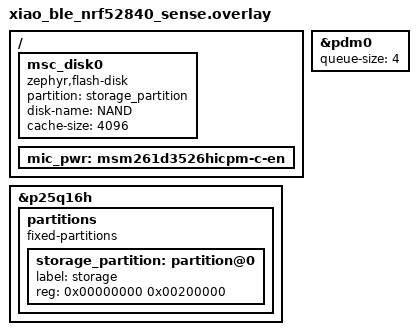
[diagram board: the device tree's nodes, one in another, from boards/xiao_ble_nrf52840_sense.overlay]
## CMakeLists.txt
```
#-------------------------------------------------------------------------------
# Zephyr Example Application
#
# Copyright (c) 2021 Nordic Semiconductor ASA
# SPDX-License-Identifier: Apache-2.0

cmake_minimum_required(VERSION 3.13.1)

# ZEPHYR_EXTRA_MODULES must be set BEFORE find_package(Zephyr) so that
# the module is discovered and its CMakeLists.txt (zephyr_include_directories,
# zephyr_library_sources, …) is processed during the Zephyr configuration.
list(APPEND ZEPHYR_EXTRA_MODULES ${CMAKE_CURRENT_SOURCE_DIR}/model)

find_package(Zephyr REQUIRED HINTS $ENV{ZEPHYR_BASE})

project(app LANGUAGES C CXX)

target_sources(app PRIVATE src/main.c)

if(CONFIG_APP_PITCH OR CONFIG_APP_REC OR CONFIG_APP_KWS)
    target_sources(app PRIVATE src/mic.c)
endif()
if(CONFIG_APP_PITCH)
    target_sources(app PRIVATE src/pitch.c)
endif()
if(CONFIG_APP_REC)
    target_sources(app PRIVATE src/rec.c)
endif()
if(CONFIG_APP_KWS)
    target_sources(app PRIVATE src/kws.cpp)
endif()
if(CONFIG_APP_DISPLAY_UI)
    target_sources(app PRIVATE src/display_ui.c)
endif()
if(CONFIG_APP_IMU)
    target_sources(app PRIVATE src/imu.c)
endif()
```

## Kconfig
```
# Copyright (c) 2021 Nordic Semiconductor ASA
# SPDX-License-Identifier: Apache-2.0
#
# This file is the application Kconfig entry point. All application Kconfig
# options can be defined here or included via other application Kconfig files.
# You can browse these options using the west targets menuconfig (terminal) or
# guiconfig (GUI).

menu "Zephyr"
source "Kconfig.zephyr"
endmenu

module = APP
module-str = APP
source "subsys/logging/Kconfig.template.log_config"

config APP_PITCH
	bool "Pitch detection"
	help
	  Real-time monophonic pitch detector (MPM algorithm).
	  Shell commands: pitch start/stop/status.

config APP_REC
	bool "WAV recording"
	help
	  WAV recording to the external QSPI flash via FAT.
	  Requires FILE_SYSTEM and FAT_FILESYSTEM_ELM.
	  Shell commands: record start/stop/status.

config APP_KWS
	bool "Keyword spotting"
	help
	  Keyword spotting using the Edge Impulse SDK.
	  Requires EDGE_IMPULSE_SDK, CPP, and GLIBCXX_LIBCPP.
	  Shell commands: kws start/stop/status.

config APP_IMU
	bool "IMU motion detection"
	default y
	depends on I2C && GPIO
	help
	  Enable significant motion detection using the LSM6DS3TR-C IMU on
	  the XIAO BLE Sense.  Events are logged at INF level via the "imu"
	  log module.  The module starts automatically at boot via SYS_INIT.
	  Requires LSM6DSL_TRIGGER_NONE so that this module owns the INT1
	  GPIO line (set CONFIG_LSM6DSL_TRIGGER_NONE=y in prj.conf).

config APP_DISPLAY_UI
	bool "Round display UI (LVGL)"
	depends on LVGL && DISPLAY && APP_PITCH
	select LV_FONT_MONTSERRAT_32
	help
	  Enable the LVGL-based round display UI for the Seeed XIAO Round Display.
	  Build with --shield seeed_xiao_round_display.
```

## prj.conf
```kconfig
# Copyright (c) 2021 Nordic Semiconductor ASA
# SPDX-License-Identifier: Apache-2.0
#
# This file contains selected Kconfig options for the application.

# ---------------------------------------------------------------------------
# USB device (CDC-ACM shell); MSC disk is added by rec.conf
# ---------------------------------------------------------------------------
CONFIG_USB_DEVICE_STACK_NEXT=y
CONFIG_CDC_ACM_SERIAL_INITIALIZE_AT_BOOT=n
CONFIG_FLASH=y
# See Nordic known issue NCSDK-40096
CONFIG_UDC_BUF_POOL_SIZE=8192

# ---------------------------------------------------------------------------
# Round display UI – Seeed XIAO Round Display + LVGL
# ---------------------------------------------------------------------------
CONFIG_DISPLAY=y
CONFIG_LVGL=y
CONFIG_LV_Z_MEM_POOL_SYS_HEAP=y
# ~50 LVGL objects across the four screens; exhausting this pool trips
# LV_USE_ASSERT_MALLOC, which spins forever and starves the shell thread.
CONFIG_LV_Z_MEM_POOL_SIZE=49152
CONFIG_SPI=y
CONFIG_I2C=y
CONFIG_INPUT=y
CONFIG_LV_Z_POINTER_FROM_CHOSEN_TOUCH=y
CONFIG_APP_DISPLAY_UI=y

# Hardware info – used to generate a unique USB serial-number string
CONFIG_HWINFO=y

# ---------------------------------------------------------------------------
# Entropy / random number generator (required by the note game)
# ---------------------------------------------------------------------------
CONFIG_ENTROPY_GENERATOR=y

# ---------------------------------------------------------------------------
# IMU motion/tap detection – LSM6DS3TR-C
# ---------------------------------------------------------------------------
# SENSOR enables the subsystem (required for the lsm6dsl driver to compile).
# Use no-trigger mode so the imu module owns the INT1 GPIO line itself.
CONFIG_SENSOR=y
CONFIG_LSM6DSL_TRIGGER_NONE=y

# ---------------------------------------------------------------------------
# PDM microphone (used by pitch detection)
# ---------------------------------------------------------------------------
CONFIG_AUDIO=y
CONFIG_AUDIO_DMIC=y

# Regulator API (already selected by board defconfig; listed here for clarity)
CONFIG_REGULATOR=y

# Enable USB device stack internal warnings so enumeration issues are visible
CONFIG_USBD_LOG_LEVEL_WRN=y

# ---------------------------------------------------------------------------
# Shell (available immediately via USB CDC-ACM)
# ---------------------------------------------------------------------------
CONFIG_SHELL=y
CONFIG_SHELL_BACKEND_SERIAL=y
CONFIG_SHELL_STACK_SIZE=4096

CONFIG_LOG=y
CONFIG_MAIN_STACK_SIZE=4096

# Floating-point unit – required by pitch detection (MPM uses float math)
CONFIG_FPU=y

CONFIG_HEAP_MEM_POOL_SIZE=32768

# ---------------------------------------------------------------------------
# Application modules
# ---------------------------------------------------------------------------
CONFIG_APP_PITCH=y
```

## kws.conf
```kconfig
# Keyword spotting fragment
# Usage: west build ... -- -DEXTRA_CONF_FILE=kws.conf
CONFIG_APP_KWS=y

# C++ support required by the Edge Impulse SDK
CONFIG_CPP=y
CONFIG_GLIBCXX_LIBCPP=y

CONFIG_EDGE_IMPULSE_SDK=y
```

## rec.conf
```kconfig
# WAV recording fragment
# Usage: west build ... -- -DEXTRA_CONF_FILE=rec.conf
CONFIG_APP_REC=y

# Flash partition map and page-layout info (required by the disk driver)
CONFIG_FLASH_MAP=y
CONFIG_FLASH_PAGE_LAYOUT=y

# Expose the QSPI flash partition as a USB-MSC block device
CONFIG_DISK_DRIVER_FLASH=y
CONFIG_USBD_MSC_CLASS=y

# FAT filesystem on the QSPI flash
CONFIG_FILE_SYSTEM=y
CONFIG_FAT_FILESYSTEM_ELM=y
CONFIG_FS_FATFS_MOUNT_MKFS=y
CONFIG_FS_FATFS_EXTRA_NATIVE_API=y
```

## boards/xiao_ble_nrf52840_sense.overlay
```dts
/*
 * Copyright (c) 2024 Nordic Semiconductor ASA
 * SPDX-License-Identifier: Apache-2.0
 *
 * Expose the 2 MB on-board QSPI flash (P25Q16H) as a USB Mass Storage disk.
 * Enable the on-board PDM microphone for audio recording.
 *
 * The internal-flash storage_partition defined in
 * nrf52840_partition_uf2_sdv7.dtsi is deleted and re-created on the external
 * QSPI flash instead.  The msc_disk0 node ties the partition to the USB MSC
 * "NAND" LUN declared in main.c.
 */

/delete-node/ &storage_partition;

&p25q16h {
	partitions {
		compatible = "fixed-partitions";
		#address-cells = <1>;
		#size-cells = <1>;

		storage_partition: partition@0 {
			label = "storage";
			reg = <0x00000000 0x00200000>; /* 2 MB */
		};
	};
};

/ {
	msc_disk0 {
		compatible = "zephyr,flash-disk";
		partition = <&storage_partition>;
		disk-name = "NAND";
		cache-size = <4096>;
	};

	/* Add a label to the microphone power regulator so C code can obtain
	 * the device via DT_NODELABEL(mic_pwr) and call regulator_enable(). */
	mic_pwr: msm261d3526hicpm-c-en {};
};

/* PDM0 is disabled by default in the nRF52840 DTSI; enable it here.
 * The recording design uses a separate FAT-writer thread so the PDM reader
 * frees slab blocks almost immediately (just a memcpy).  queue-size=4 is
 * therefore sufficient: 2 (HW double-buffer) + 2 (rx_queue margin) = 4. */
&pdm0 {
	status = "okay";
	queue-size = <4>;
};
```

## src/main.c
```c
/*
 * Copyright (c) 2021 Nordic Semiconductor ASA
 * SPDX-License-Identifier: Apache-2.0
 */

#include <zephyr/kernel.h>
#include <zephyr/logging/log.h>
#include <zephyr/usb/usbd.h>
#if IS_ENABLED(CONFIG_APP_REC)
#include <zephyr/usb/class/usbd_msc.h>
#include <zephyr/storage/disk_access.h>
#endif

#include <app_version.h>

LOG_MODULE_REGISTER(main, CONFIG_APP_LOG_LEVEL);

/* ===========================================================================
 * USB device setup (CDC-ACM shell; composite with MSC when APP_REC is enabled)
 * =========================================================================== */

/* VID 0x2FE3 is the Zephyr project vendor ID -- replace with your own. */
USBD_DEVICE_DEFINE(usbd_dev,
   DEVICE_DT_GET(DT_NODELABEL(zephyr_udc0)),
   0x2FE3, 0x0008);

USBD_DESC_LANG_DEFINE(usbd_lang);
USBD_DESC_MANUFACTURER_DEFINE(usbd_mfr, "Seeed Studio");
#if IS_ENABLED(CONFIG_APP_REC)
USBD_DESC_PRODUCT_DEFINE(usbd_product, "XIAO BLE Flash Disk");
#else
USBD_DESC_PRODUCT_DEFINE(usbd_product, "XIAO BLE Microphone");
#endif

#if defined(CONFIG_HWINFO)
USBD_DESC_SERIAL_NUMBER_DEFINE(usbd_sn);
#endif

USBD_DESC_CONFIG_DEFINE(usbd_fs_cfg_desc, "FS Configuration");
USBD_CONFIGURATION_DEFINE(usbd_fs_config, 0, 125, &usbd_fs_cfg_desc);

#if IS_ENABLED(CONFIG_APP_REC)
/* "NAND" must match disk-name in the board overlay */
USBD_DEFINE_MSC_LUN(nand, "NAND", "Seeed", "XIAO Flash", "0.01");
#endif

static const char *const usbd_blocklist[] = {NULL};

/* ===========================================================================
 * main -- init USB (and flash disk when APP_REC is enabled), then idle
 * =========================================================================== */

int main(void)
{
int ret;

#if IS_ENABLED(CONFIG_APP_REC)
ret = disk_access_init("NAND");
if (ret) {
LOG_ERR("disk_access_init: %d", ret);
return ret;
}
#endif

ret = usbd_add_descriptor(&usbd_dev, &usbd_lang);
if (ret) {
LOG_ERR("lang descriptor: %d", ret);
return ret;
}
ret = usbd_add_descriptor(&usbd_dev, &usbd_mfr);
if (ret) {
LOG_ERR("mfr descriptor: %d", ret);
return ret;
}
ret = usbd_add_descriptor(&usbd_dev, &usbd_product);
if (ret) {
LOG_ERR("product descriptor: %d", ret);
return ret;
}
#if defined(CONFIG_HWINFO)
ret = usbd_add_descriptor(&usbd_dev, &usbd_sn);
if (ret) {
LOG_ERR("sn descriptor: %d", ret);
return ret;
}
#endif
ret = usbd_add_configuration(&usbd_dev, USBD_SPEED_FS,
     &usbd_fs_config);
if (ret) {
LOG_ERR("add_configuration: %d", ret);
return ret;
}
ret = usbd_register_all_classes(&usbd_dev, USBD_SPEED_FS, 1,
usbd_blocklist);
if (ret) {
LOG_ERR("register_all_classes: %d", ret);
return ret;
}
#if defined(CONFIG_USBD_CDC_ACM_CLASS)
ret = usbd_device_set_code_triple(&usbd_dev, USBD_SPEED_FS,
  USB_BCC_MISCELLANEOUS, 0x02, 0x01);
if (ret) {
LOG_ERR("set_code_triple: %d", ret);
return ret;
}
#endif
ret = usbd_init(&usbd_dev);
if (ret) {
LOG_ERR("usbd_init: %d", ret);
return ret;
}
ret = usbd_enable(&usbd_dev);
if (ret) {
LOG_ERR("usbd_enable: %d", ret);
return ret;
}

LOG_INF("XIAO BLE Microphone ready (app %s) -- "
"connect USB and open the serial port", APP_VERSION_STRING);

while (true) {
k_sleep(K_SECONDS(1));
}

return 0;
}
```

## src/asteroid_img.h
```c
#pragma once
#include <lvgl.h>

static const uint8_t asteroid_img_map[] = {
    0x00, 0x00, 0x00, 0x00, 0x00, 0x00, 0x00, 0x00, 0x00, 0x00, 0xAA, 0x52,
    0xFF, 0xFF, 0x00, 0x00, 0x00, 0x00, 0xE8, 0x39, 0x8F, 0x6B, 0x31, 0x7C,
    0x6E, 0x6B, 0xA6, 0x31, 0x00, 0x00, 0x00, 0x00, 0x00, 0x00, 0xFF, 0x7F,
    0x00, 0x00, 0x00, 0x00, 0x00, 0x00, 0x00, 0x00, 0x00, 0x00, 0x00, 0x00,
    0x00, 0x00, 0xAA, 0x52, 0x00, 0x00, 0x00, 0x00, 0x00, 0x00, 0x82, 0x10,
    0x2D, 0x5B, 0x56, 0xA5, 0xF8, 0xB5, 0x35, 0x9D, 0xF4, 0x94, 0x15, 0x95,
    0x31, 0x7C, 0x8A, 0x4A, 0x00, 0x00, 0x00, 0x00, 0xFF, 0xFF, 0x00, 0x00,
    0x00, 0x00, 0x00, 0x00, 0x00, 0x00, 0x00, 0x00, 0x00, 0x00, 0x00, 0x00,
    0x00, 0x00, 0xE4, 0x18, 0x2D, 0x63, 0xD4, 0x8C, 0xD8, 0xAD, 0x97, 0xA5,
    0x97, 0xA5, 0x93, 0x8C, 0xCF, 0x73, 0xAF, 0x6B, 0x10, 0x74, 0x76, 0xA5,
    0xB3, 0x8C, 0xE8, 0x39, 0x00, 0x00, 0x55, 0xAD, 0x00, 0x00, 0x00, 0x00,
    0x00, 0x00, 0x00, 0x00, 0x00, 0x00, 0x29, 0x42, 0xAF, 0x6B, 0xF4, 0x94,
    0xD8, 0xAD, 0xD8, 0xAD, 0xB8, 0xAD, 0xD8, 0xAD, 0x97, 0xA5, 0xB7, 0xAD,
    0xD8, 0xAD, 0xB7, 0xAD, 0xB3, 0x8C, 0x2D, 0x5B, 0x35, 0x9D, 0x77, 0xA5,
    0xA6, 0x31, 0x00, 0x00, 0xEF, 0x7B, 0x00, 0x00, 0xFF, 0xFF, 0x00, 0x00,
    0x8F, 0x6B, 0xD4, 0x94, 0xB3, 0x8C, 0xD8, 0xAD, 0xB7, 0xAD, 0xF4, 0x94,
    0xF0, 0x73, 0xF0, 0x73, 0x56, 0xA5, 0x97, 0xA5, 0x97, 0xA5, 0x76, 0xA5,
    0xD8, 0xAD, 0x56, 0xA5, 0xD4, 0x8C, 0xF9, 0xB5, 0x93, 0x8C, 0xC3, 0x10,
    0x00, 0x00, 0xAA, 0x52, 0x00, 0x00, 0xCB, 0x52, 0x97, 0xA5, 0x2D, 0x63,
    0x15, 0x9D, 0xD8, 0xAD, 0xF0, 0x73, 0x0D, 0x5B, 0x11, 0x74, 0xAF, 0x63,
    0x8F, 0x6B, 0xF8, 0xB5, 0x15, 0x95, 0xEC, 0x52, 0xAF, 0x6B, 0xB7, 0xAD,
    0xB7, 0xAD, 0x76, 0xA5, 0xD8, 0xAD, 0xD0, 0x73, 0x00, 0x00, 0x00, 0x00,
    0x00, 0x00, 0x31, 0x7C, 0xAF, 0x6B, 0xF4, 0x94, 0x19, 0xB6, 0x93, 0x8C,
    0x2E, 0x5B, 0xF5, 0x8C, 0x36, 0x95, 0xF1, 0x6B, 0xAF, 0x6B, 0xF8, 0xB5,
    0x4E, 0x63, 0x72, 0x7C, 0x2D, 0x5B, 0x56, 0xA5, 0x76, 0xA5, 0xB7, 0xAD,
    0xB7, 0xAD, 0x3A, 0xBE, 0x0C, 0x5B, 0x00, 0x00, 0x41, 0x08, 0x93, 0x8C,
    0xF4, 0x94, 0x97, 0xA5, 0xD8, 0xAD, 0x31, 0x7C, 0x4E, 0x5B, 0x73, 0x7C,
    0x8F, 0x63, 0x2D, 0x5B, 0x76, 0xA5, 0x97, 0xA5, 0x4D, 0x5B, 0x6F, 0x63,
    0xCF, 0x73, 0xB7, 0xAD, 0xB7, 0xAD, 0xF4, 0x94, 0x4E, 0x63, 0x11, 0x7C,
    0x35, 0x9D, 0xE3, 0x18, 0xA7, 0x31, 0x56, 0xA5, 0xB8, 0xAD, 0x76, 0xA5,
    0x77, 0xA5, 0x97, 0xA5, 0xF0, 0x73, 0x8F, 0x6B, 0x31, 0x7C, 0x97, 0xA5,
    0x97, 0xA5, 0xB7, 0xAD, 0xB3, 0x8C, 0xD0, 0x73, 0x77, 0xA5, 0xB8, 0xAD,
    0xD4, 0x94, 0xEC, 0x52, 0x73, 0x7C, 0x4E, 0x5B, 0x93, 0x8C, 0xEC, 0x5A,
    0x49, 0x42, 0x97, 0xA5, 0x97, 0xA5, 0xD8, 0xAD, 0xB7, 0xAD, 0x97, 0xA5,
    0xD8, 0xAD, 0xB8, 0xAD, 0xD8, 0xAD, 0x97, 0xA5, 0x77, 0xA5, 0x77, 0xA5,
    0xD8, 0xAD, 0xD8, 0xAD, 0x97, 0xA5, 0x97, 0xA5, 0x2D, 0x5B, 0x73, 0x7C,
    0x15, 0x8D, 0xB0, 0x6B, 0xB3, 0x8C, 0xCF, 0x6B, 0x6A, 0x4A, 0x97, 0xA5,
    0xB7, 0xAD, 0x72, 0x84, 0xD4, 0x8C, 0xB7, 0xAD, 0x76, 0xA5, 0x76, 0xA5,
    0x76, 0xA5, 0x77, 0xA5, 0x77, 0xA5, 0xB7, 0xAD, 0xAF, 0x6B, 0x56, 0x9D,
    0xB8, 0xAD, 0xD4, 0x94, 0x6E, 0x63, 0xD4, 0x8C, 0xB4, 0x84, 0x2D, 0x5B,
    0x76, 0xA5, 0xD0, 0x73, 0x8A, 0x4A, 0xF8, 0xB5, 0x31, 0x7C, 0x0D, 0x53,
    0x2D, 0x5B, 0x76, 0xA5, 0x97, 0xA5, 0x97, 0xA5, 0x97, 0xA5, 0xB7, 0xAD,
    0xF9, 0xB5, 0xCF, 0x73, 0xF0, 0x73, 0xB8, 0xAD, 0xB7, 0xAD, 0x93, 0x8C,
    0x6E, 0x63, 0x15, 0x8D, 0x4E, 0x5B, 0xF0, 0x73, 0x19, 0xB6, 0x8F, 0x6B,
    0x0D, 0x5B, 0xD8, 0xAD, 0x2D, 0x5B, 0x93, 0x84, 0x4E, 0x5B, 0x76, 0xA5,
    0x97, 0xA5, 0x97, 0xA5, 0x97, 0xA5, 0x35, 0x9D, 0x6E, 0x63, 0xCF, 0x73,
    0xD8, 0xAD, 0x77, 0xA5, 0x97, 0xA5, 0x76, 0xA5, 0x4E, 0x63, 0x2D, 0x5B,
    0xF0, 0x73, 0xB7, 0xAD, 0xB8, 0xAD, 0xCB, 0x52, 0x8F, 0x6B, 0xF8, 0xB5,
    0xAF, 0x6B, 0xCC, 0x52, 0xB3, 0x8C, 0xB8, 0xAD, 0x76, 0xA5, 0x97, 0xAD,
    0x35, 0x9D, 0x6E, 0x63, 0xB3, 0x8C, 0xD8, 0xAD, 0x77, 0xA5, 0x97, 0xA5,
    0x97, 0xA5, 0x97, 0xA5, 0x97, 0xA5, 0x56, 0x9D, 0xB8, 0xAD, 0xB7, 0xAD,
    0xD4, 0x94, 0xC3, 0x10, 0x2D, 0x63, 0xD8, 0xAD, 0x76, 0xA5, 0x35, 0x9D,
    0xB7, 0xAD, 0x77, 0xA5, 0x97, 0xA5, 0x97, 0xA5, 0x76, 0xA5, 0xB8, 0xAD,
    0xF8, 0xB5, 0x97, 0xA5, 0x77, 0xA5, 0x97, 0xA5, 0x97, 0xA5, 0x77, 0xA5,
    0x77, 0xA5, 0x97, 0xA5, 0x76, 0xA5, 0xF8, 0xB5, 0x8E, 0x6B, 0x00, 0x00,
    0x65, 0x29, 0x15, 0x9D, 0xB7, 0xAD, 0x97, 0xA5, 0x77, 0xA5, 0x77, 0xA5,
    0x97, 0xA5, 0x77, 0xA5, 0xB7, 0xAD, 0x76, 0xA5, 0xD4, 0x94, 0x35, 0x9D,
    0xB7, 0xAD, 0x77, 0xA5, 0x76, 0xA5, 0x97, 0xAD, 0xD8, 0xAD, 0x76, 0xA5,
    0x97, 0xA5, 0x97, 0xA5, 0xC7, 0x31, 0x00, 0x00, 0x00, 0x00, 0x6E, 0x6B,
    0xF9, 0xB5, 0x76, 0xA5, 0x97, 0xA5, 0xB7, 0xAD, 0x76, 0xA5, 0x97, 0xAD,
    0x35, 0x9D, 0x4E, 0x63, 0xD0, 0x6B, 0x2D, 0x5B, 0x92, 0x84, 0xB7, 0xAD,
    0xB7, 0xAD, 0x56, 0x9D, 0x8E, 0x6B, 0x92, 0x84, 0x39, 0xBE, 0xD0, 0x73,
    0x00, 0x00, 0xFF, 0xFF, 0x00, 0x00, 0x45, 0x29, 0x35, 0x9D, 0xF9, 0xB5,
    0xB3, 0x8C, 0x52, 0x84, 0xD8, 0xAD, 0x97, 0xAD, 0xD4, 0x94, 0xCC, 0x52,
    0x52, 0x7C, 0x2D, 0x5B, 0x31, 0x7C, 0x19, 0xB6, 0xB3, 0x8C, 0x2D, 0x5B,
    0xB3, 0x8C, 0xF8, 0xB5, 0x93, 0x8C, 0x45, 0x21, 0x00, 0x00, 0xAA, 0x52,
    0xFF, 0xFF, 0x00, 0x00, 0x49, 0x42, 0x56, 0x9D, 0xD8, 0xAD, 0x2D, 0x5B,
    0xD4, 0x94, 0xD8, 0xB5, 0x97, 0xAD, 0xD4, 0x94, 0x11, 0x7C, 0xB3, 0x8C,
    0xD8, 0xAD, 0xF4, 0x94, 0x2D, 0x5B, 0x76, 0xA5, 0x19, 0xB6, 0xD3, 0x8C,
    0x65, 0x29, 0x00, 0x00, 0xAA, 0x52, 0x00, 0x00, 0x00, 0x00, 0xFF, 0xFF,
    0x00, 0x00, 0x86, 0x29, 0x72, 0x84, 0xD8, 0xAD, 0x2D, 0x5B, 0x92, 0x84,
    0x97, 0xA5, 0x97, 0xAD, 0xB8, 0xAD, 0xB7, 0xAD, 0x97, 0xA5, 0x4E, 0x63,
    0x56, 0x9D, 0x19, 0xB6, 0xF4, 0x94, 0x86, 0x29, 0x00, 0x00, 0xEF, 0x7B,
    0x00, 0x00, 0x00, 0x00, 0x00, 0x00, 0x00, 0x00, 0xFF, 0xFF, 0x00, 0x00,
    0x00, 0x00, 0xAF, 0x6B, 0x97, 0xA5, 0x10, 0x74, 0x76, 0xA5, 0xD8, 0xAD,
    0xB8, 0xAD, 0xD8, 0xAD, 0xB8, 0xAD, 0x97, 0xAD, 0xF8, 0xB5, 0x52, 0x84,
    0x86, 0x29, 0x00, 0x00, 0xEF, 0x7B, 0x00, 0x00, 0x00, 0x00, 0x00, 0x00,
    0x00, 0x00, 0x00, 0x00, 0x00, 0x00, 0xEF, 0x39, 0x00, 0x00, 0x00, 0x00,
    0x69, 0x42, 0xF0, 0x73, 0xF0, 0x73, 0xF0, 0x73, 0x8E, 0x6B, 0x4D, 0x63,
    0x6E, 0x63, 0xCF, 0x73, 0xEC, 0x5A, 0x21, 0x00, 0x00, 0x00, 0x55, 0xAD,
    0x00, 0x00, 0x00, 0x00, 0x00, 0x00, 0x00, 0x00, 0x00, 0x00, 0x00, 0x00,
    0x01, 0x03, 0x01, 0x00, 0x07, 0x87, 0xE7, 0xF8, 0xD0, 0x70, 0x17, 0x00,
    0x00, 0x02, 0x00, 0x00, 0x00, 0x00, 0x00, 0x00, 0x01, 0x03, 0x00, 0x00,
    0x00, 0x47, 0xC3, 0xFF, 0xFF, 0xFB, 0xFF, 0xFF, 0xE5, 0x93, 0x34, 0x00,
    0x01, 0x00, 0x00, 0x00, 0x00, 0x01, 0x00, 0x00, 0x04, 0x52, 0xC1, 0xFF,
    0xFF, 0xFC, 0xFE, 0xF6, 0xF0, 0xEF, 0xF7, 0xFF, 0xFF, 0x90, 0x00, 0x03,
    0x01, 0x00, 0x01, 0x00, 0x13, 0x7C, 0xD2, 0xFF, 0xFF, 0xFF, 0xFE, 0xFF,
    0xFF, 0xFF, 0xFF, 0xFF, 0xF8, 0xEB, 0xF6, 0xFF, 0x7F, 0x00, 0x04, 0x00,
    0x01, 0x1F, 0xD6, 0xFF, 0xFB, 0xFD, 0xFD, 0xF8, 0xF5, 0xF6, 0xFD, 0xFF,
    0xFF, 0xFE, 0xFF, 0xFE, 0xF8, 0xFB, 0xFF, 0x51, 0x00, 0x03, 0x00, 0xA8,
    0xFF, 0xE4, 0xF9, 0xFF, 0xF3, 0xF0, 0xFA, 0xF8, 0xF3, 0xFF, 0xFA, 0xEE,
    0xF3, 0xFF, 0xFF, 0xFD, 0xFE, 0xEF, 0x2A, 0x00, 0x15, 0xE9, 0xF1, 0xFA,
    0xFF, 0xF6, 0xF1, 0xFF, 0xFF, 0xF9, 0xF4, 0xFF, 0xF0, 0xFD, 0xF6, 0xFE,
    0xFF, 0xFF, 0xFE, 0xFF, 0xCB, 0x0A, 0x44, 0xFC, 0xF8, 0xFF, 0xFF, 0xF2,
    0xF2, 0xFB, 0xF5, 0xEF, 0xFD, 0xFE, 0xEE, 0xF5, 0xF3, 0xFF, 0xFF, 0xFA,
    0xEE, 0xF0, 0xFF, 0x58, 0x78, 0xFF, 0xFE, 0xFE, 0xFF, 0xFE, 0xF2, 0xEE,
    0xF5, 0xFE, 0xFF, 0xFF, 0xFA, 0xF6, 0xFF, 0xFF, 0xF9, 0xEF, 0xFB, 0xEE,
    0xFB, 0xA7, 0x8A, 0xFF, 0xFC, 0xFF, 0xFF, 0xFF, 0xFF, 0xFF, 0xFF, 0xFF,
    0xFF, 0xFF, 0xFF, 0xFF, 0xFF, 0xFE, 0xF0, 0xFD, 0xFF, 0xF3, 0xF9, 0xDD,
    0x8D, 0xFF, 0xFE, 0xF5, 0xF7, 0xFF, 0xFF, 0xFF, 0xFF, 0xFF, 0xFF, 0xFF,
    0xF1, 0xFD, 0xFF, 0xF8, 0xF3, 0xFF, 0xFF, 0xEF, 0xFF, 0xE0, 0x9C, 0xFF,
    0xF4, 0xF0, 0xF5, 0xFE, 0xFF, 0xFF, 0xFF, 0xFF, 0xFF, 0xF3, 0xF5, 0xFF,
    0xFF, 0xF5, 0xF1, 0xFF, 0xF4, 0xF3, 0xFF, 0xDF, 0xC3, 0xFF, 0xEC, 0xFE,
    0xF3, 0xFE, 0xFF, 0xFF, 0xFF, 0xFA, 0xF1, 0xF4, 0xFF, 0xFF, 0xFF, 0xFE,
    0xF1, 0xF0, 0xF4, 0xFE, 0xFF, 0xB7, 0xDF, 0xFF, 0xF2, 0xF0, 0xF6, 0xFF,
    0xFE, 0xFF, 0xFA, 0xF0, 0xF9, 0xFF, 0xFF, 0xFF, 0xFF, 0xFF, 0xFE, 0xFD,
    0xFF, 0xFE, 0xFE, 0x50, 0xC7, 0xFE, 0xFD, 0xFD, 0xFF, 0xFF, 0xFF, 0xFF,
    0xFF, 0xFF, 0xFF, 0xFF, 0xFF, 0xFF, 0xFF, 0xFF, 0xFF, 0xFF, 0xFC, 0xFE,
    0xD0, 0x06, 0x61, 0xFF, 0xFD, 0xFF, 0xFF, 0xFF, 0xFF, 0xFF, 0xFF, 0xFE,
    0xF9, 0xFC, 0xFF, 0xFF, 0xFF, 0xFF, 0xFF, 0xFE, 0xFB, 0xFF, 0x70, 0x00,
    0x06, 0xCF, 0xFD, 0xFD, 0xFF, 0xFF, 0xFF, 0xFF, 0xFB, 0xEF, 0xF3, 0xF0,
    0xF9, 0xFF, 0xFF, 0xFC, 0xF1, 0xF4, 0xFF, 0xEF, 0x15, 0x01, 0x00, 0x59,
    0xFF, 0xFC, 0xF7, 0xF5, 0xFF, 0xFF, 0xF8, 0xF0, 0xFA, 0xF3, 0xF7, 0xFF,
    0xF9, 0xEF, 0xF7, 0xFD, 0xFF, 0x53, 0x00, 0x03, 0x02, 0x02, 0xA0, 0xFF,
    0xFE, 0xEE, 0xFA, 0xFF, 0xFF, 0xFB, 0xF5, 0xF9, 0xFF, 0xFA, 0xEF, 0xFD,
    0xFE, 0xFF, 0x62, 0x00, 0x03, 0x00, 0x01, 0x01, 0x00, 0x7A, 0xFE, 0xFF,
    0xEC, 0xF7, 0xFE, 0xFF, 0xFF, 0xFE, 0xFC, 0xEE, 0xFA, 0xFF, 0xFF, 0x6D,
    0x00, 0x04, 0x00, 0x00, 0x00, 0x01, 0x02, 0x00, 0x45, 0xDD, 0xFF, 0xF5,
    0xFB, 0xFF, 0xFF, 0xFF, 0xFF, 0xFF, 0xFF, 0xF6, 0x68, 0x00, 0x04, 0x00,
    0x00, 0x00, 0x00, 0x00, 0x00, 0x04, 0x00, 0x1E, 0xA3, 0xE6, 0xFA, 0xEF,
    0xD6, 0xBF, 0xD4, 0xE1, 0xB6, 0x3C, 0x00, 0x03, 0x00, 0x00, 0x00, 0x00,
};

static const lv_image_dsc_t asteroid_img = {
    .header = {
        .magic      = LV_IMAGE_HEADER_MAGIC,
        .cf         = LV_COLOR_FORMAT_NATIVE_WITH_ALPHA,
        .flags      = 0,
        .w          = 22,
        .h          = 22,
        .stride     = 44,
        .reserved_2 = 0,
    },
    .data_size = 1452,
    .data      = asteroid_img_map,
};
```

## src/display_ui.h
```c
/*
 * Copyright (c) 2026 Nicolas Goualard
 * SPDX-License-Identifier: Apache-2.0
 *
 * Round display UI – LVGL button and note label for the Seeed XIAO Round Display.
 *
 * Self-initialising: the display thread starts automatically at boot when
 * CONFIG_APP_DISPLAY_UI=y.  No explicit init call is required from main.c.
 *
 * Build with:  --shield seeed_xiao_round_display  (required for the DTS chosen
 * node zephyr,display and zephyr,touch to be present).
 */

#pragma once
```

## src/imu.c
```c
/*
 * Copyright (c) 2026 Nicolas Goualard
 * SPDX-License-Identifier: Apache-2.0
 *
 * IMU significant motion detection – LSM6DS3TR-C on XIAO BLE Sense.
 *
 * The Zephyr lsm6dsl driver is used in TRIGGER_NONE mode so that we can
 * own the INT1 GPIO line.  We configure the IMU's embedded-function engine
 * directly via I2C register writes (the driver does not expose significant-
 * motion configuration through the generic sensor API).
 *
 * Event flow:
 *   IMU asserts INT1 → GPIO edge interrupt fires imu_gpio_callback()
 *   → disables the interrupt and submits imu_work to the system work queue
 *   → imu_work_handler() reads FUNC_SRC1 to confirm the event
 *   → logs the event and re-arms the interrupt.
 */

#include "imu.h"

#include <zephyr/device.h>
#include <zephyr/devicetree.h>
#include <zephyr/drivers/gpio.h>
#include <zephyr/drivers/i2c.h>
#include <zephyr/drivers/sensor.h>
#include <zephyr/init.h>
#include <zephyr/kernel.h>
#include <zephyr/logging/log.h>

LOG_MODULE_REGISTER(imu, CONFIG_APP_LOG_LEVEL);

/* -------------------------------------------------------------------------
 * LSM6DS3TR-C register map (subset used by this module)
 * ------------------------------------------------------------------------- */
#define IMU_REG_INT1_CTRL  0x0D  /* INT1 pin function routing */
#define IMU_REG_CTRL10_C   0x19  /* Embedded-function enable  */
#define IMU_REG_FUNC_SRC1  0x53  /* Embedded-function status  */

/* CTRL10_C – embedded-function master enable + significant motion */
#define IMU_CTRL10_FUNC_EN      BIT(2)
#define IMU_CTRL10_SIGN_MOT_EN  BIT(0)

/* INT1_CTRL – route significant motion to INT1 */
#define IMU_INT1_SIGN_MOT  BIT(6)

/* FUNC_SRC1 status bits */
#define IMU_FUNC_SRC1_SIGN_MOT  BIT(6)

/* 7-bit I2C address of the LSM6DS3TR-C (matches reg = <0x6a> in DTS) */
#define IMU_I2C_ADDR  0x6AU

/* -------------------------------------------------------------------------
 * Static state
 * ------------------------------------------------------------------------- */
static const struct device *imu_i2c;

/* irq-gpios property from the lsm6ds3tr-c DTS node (gpio0 pin 11) */
static const struct gpio_dt_spec imu_int =
	GPIO_DT_SPEC_GET(DT_NODELABEL(lsm6ds3tr_c), irq_gpios);

static struct gpio_callback imu_gpio_cb;
static struct k_work imu_work;
static imu_motion_cb_t motion_cb;

/* -------------------------------------------------------------------------
 * Work-queue handler – runs in the system work queue thread
 * ------------------------------------------------------------------------- */
static void imu_work_handler(struct k_work *work)
{
	ARG_UNUSED(work);

	uint8_t func_src1 = 0;

	i2c_reg_read_byte(imu_i2c, IMU_I2C_ADDR, IMU_REG_FUNC_SRC1, &func_src1);

	if (func_src1 & IMU_FUNC_SRC1_SIGN_MOT) {
		LOG_INF("Significant motion detected");
		if (motion_cb) {
			motion_cb();
		}
	}

	/* Re-arm the interrupt for the next event. */
	gpio_pin_interrupt_configure_dt(&imu_int, GPIO_INT_EDGE_TO_ACTIVE);
}

/* -------------------------------------------------------------------------
 * GPIO interrupt callback – runs in ISR context
 * ------------------------------------------------------------------------- */
static void imu_gpio_callback(const struct device *port,
			      struct gpio_callback *cb, uint32_t pins)
{
	ARG_UNUSED(port);
	ARG_UNUSED(cb);
	ARG_UNUSED(pins);

	/* Disable the interrupt until the work handler has read the status. */
	gpio_pin_interrupt_configure_dt(&imu_int, GPIO_INT_DISABLE);
	k_work_submit(&imu_work);
}

/* -------------------------------------------------------------------------
 * Register configuration
 * ------------------------------------------------------------------------- */
static int imu_configure(void)
{
	int ret;

	/* Enable embedded functions and significant motion. */
	ret = i2c_reg_write_byte(imu_i2c, IMU_I2C_ADDR, IMU_REG_CTRL10_C,
				 IMU_CTRL10_FUNC_EN | IMU_CTRL10_SIGN_MOT_EN);
	if (ret) {
		return ret;
	}

	/* Route significant motion to INT1. */
	return i2c_reg_write_byte(imu_i2c, IMU_I2C_ADDR, IMU_REG_INT1_CTRL,
				  IMU_INT1_SIGN_MOT);
}

/* -------------------------------------------------------------------------
 * Public API
 * ------------------------------------------------------------------------- */
int imu_init(void)
{
	int ret;

	/* Obtain the I2C controller that the sensor node sits on. */
	imu_i2c = DEVICE_DT_GET(DT_BUS(DT_NODELABEL(lsm6ds3tr_c)));
	if (!device_is_ready(imu_i2c)) {
		LOG_ERR("I2C bus not ready");
		return -ENODEV;
	}

	/* Enable accelerometer – required for the significant motion engine. */
	const struct device *imu_dev =
		DEVICE_DT_GET(DT_NODELABEL(lsm6ds3tr_c));
	if (!device_is_ready(imu_dev)) {
		LOG_ERR("LSM6DS3TR-C not ready");
		return -ENODEV;
	}

	struct sensor_value odr = { .val1 = 104, .val2 = 0 };
	ret = sensor_attr_set(imu_dev, SENSOR_CHAN_ACCEL_XYZ,
			      SENSOR_ATTR_SAMPLING_FREQUENCY, &odr);
	if (ret) {
		LOG_ERR("accel ODR set: %d", ret);
		return ret;
	}

	/* Set up the INT1 GPIO line. */
	if (!gpio_is_ready_dt(&imu_int)) {
		LOG_ERR("INT GPIO not ready");
		return -ENODEV;
	}

	ret = gpio_pin_configure_dt(&imu_int, GPIO_INPUT);
	if (ret) {
		LOG_ERR("gpio_pin_configure_dt: %d", ret);
		return ret;
	}

	k_work_init(&imu_work, imu_work_handler);

	gpio_init_callback(&imu_gpio_cb, imu_gpio_callback, BIT(imu_int.pin));
	ret = gpio_add_callback(imu_int.port, &imu_gpio_cb);
	if (ret) {
		LOG_ERR("gpio_add_callback: %d", ret);
		return ret;
	}

	/* Write embedded-function and interrupt configuration registers. */
	ret = imu_configure();
	if (ret) {
		LOG_ERR("imu_configure: %d", ret);
		return ret;
	}

	/* Arm the interrupt – ready to receive events. */
	ret = gpio_pin_interrupt_configure_dt(&imu_int, GPIO_INT_EDGE_TO_ACTIVE);
	if (ret) {
		LOG_ERR("gpio_pin_interrupt_configure_dt: %d", ret);
		return ret;
	}

	LOG_INF("IMU ready – significant motion detection active");
	return 0;
}

void imu_set_motion_cb(imu_motion_cb_t cb)
{
	motion_cb = cb;
}

SYS_INIT(imu_init, APPLICATION, CONFIG_APPLICATION_INIT_PRIORITY);
```

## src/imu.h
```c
/*
 * Copyright (c) 2026 Nicolas Goualard
 * SPDX-License-Identifier: Apache-2.0
 *
 * IMU significant motion detection for the LSM6DS3TR-C on XIAO BLE Sense.
 *
 * Detects significant motion and logs the event.
 * Starts automatically at boot when APP_IMU is enabled.
 */

#pragma once

#ifdef __cplusplus
extern "C" {
#endif

/** Called from the system work queue when significant motion is confirmed. */
typedef void (*imu_motion_cb_t)(void);

#if CONFIG_APP_IMU
/** Initialise the IMU motion-event module.
 *
 *  Called automatically by SYS_INIT; exposed here so callers can check
 *  the return value during testing or manual bringup.
 *
 *  @return 0 on success, negative errno on failure.
 */
int imu_init(void);

/** Register a callback invoked on every confirmed significant-motion event. */
void imu_set_motion_cb(imu_motion_cb_t cb);
#else
static inline int imu_init(void) { return 0; }
static inline void imu_set_motion_cb(imu_motion_cb_t cb) { ARG_UNUSED(cb); }
#endif

#ifdef __cplusplus
}
#endif
```

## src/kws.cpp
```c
/*
 * Copyright (c) 2026 Nicolas Goualard
 * SPDX-License-Identifier: Apache-2.0
 *
 * Keyword Spotting (KWS) mode using the Edge Impulse SDK.
 *
 * This file is the SINGLE translation unit that includes ei_run_classifier.h
 * (all its extern "C" function bodies – run_classifier_init, run_classifier_continuous,
 * process_impulse_continuous, etc. – are defined there).
 *
 * Shell commands:
 *   kws start   – start continuous keyword detection
 *   kws stop    – stop keyword detection
 *   kws status  – print current state and label list
 *
 * The inference runs in a dedicated thread that reads PDM slices of
 * EI_CLASSIFIER_SLICE_SIZE samples and feeds them to run_classifier_continuous().
 * This implements a sliding-window approach: every slice triggers one DSP + inference
 * step; the SDK keeps the rolling feature matrix internally.
 */

#include "kws.h"
#include "pitch.h"

#include <string.h>
#include <stdlib.h>

#include <zephyr/kernel.h>
#include <zephyr/logging/log.h>
#include <zephyr/shell/shell.h>
#include "mic.h"

/*
 * Edge Impulse SDK.
 * ei_run_classifier.h includes model-parameters/model_metadata.h and
 * model-parameters/model_variables.h, both found under the model directory
 * that is added to the include path by the model module's CMakeLists.txt.
 */
#include "edge-impulse-sdk/classifier/ei_run_classifier.h"

LOG_MODULE_REGISTER(kws, CONFIG_APP_LOG_LEVEL);

#include "rec.h"
#include "pitch.h"

/* =========================================================================
 * Inference slice buffer.
 * EI_CLASSIFIER_SLICE_SIZE = EI_CLASSIFIER_RAW_SAMPLE_COUNT / SLICES_PER_MODEL_WINDOW
 *                          = 15488 / 4 = 3872 samples (~242 ms at 16 kHz).
 * MIC_BLOCK_SAMPLES (1600) are accumulated here until a full slice is ready.
 * ========================================================================= */

#define KWS_SLICE_SAMPLES  EI_CLASSIFIER_SLICE_SIZE

static int16_t kws_slice_buf[KWS_SLICE_SAMPLES];
static size_t  kws_slice_fill;

/* =========================================================================
 * Detection threshold
 * ========================================================================= */

/*
 * Only log a label when its confidence score is >= this value.
 * Initialised from the model metadata default; the user can change it at
 * run-time with "kws threshold <value>".
 */
static float kws_threshold = (float)EI_CLASSIFIER_THRESHOLD;

/* =========================================================================
 * KWS state
 * ========================================================================= */

static K_MUTEX_DEFINE(kws_mutex);
static bool     kws_active;
static atomic_t kws_stop_req = ATOMIC_INIT(0);

#define KWS_STACK_SIZE  8192
static K_THREAD_STACK_DEFINE(kws_stack, KWS_STACK_SIZE);
static struct k_thread kws_thread;

/* =========================================================================
 * EI signal_t callback
 * Normalises int16 PCM samples from kws_slice_buf to float [-1.0, 1.0].
 * ========================================================================= */

static int kws_get_data(size_t offset, size_t length, float *out_ptr)
{
    for (size_t i = 0; i < length; i++) {
        out_ptr[i] = (float)kws_slice_buf[offset + i] / 32768.0f;
    }
    return EIDSP_OK;
}

/* =========================================================================
 * KWS inference thread
 * ========================================================================= */

/* PDM block callback: accumulate samples into the slice buffer and run
 * inference whenever a full slice is ready. */
static void kws_block_cb(void *buf, uint32_t size, void *user_data)
{
    ARG_UNUSED(user_data);

    const int16_t *src     = (const int16_t *)buf;
    size_t         samples = size / sizeof(int16_t);
    size_t         pos     = 0;

    while (pos < samples) {
        size_t space   = (size_t)KWS_SLICE_SAMPLES - kws_slice_fill;
        size_t to_copy = (samples - pos < space) ? (samples - pos) : space;

        memcpy(&kws_slice_buf[kws_slice_fill], &src[pos],
               to_copy * sizeof(int16_t));
        kws_slice_fill += to_copy;
        pos            += to_copy;

        if (kws_slice_fill == (size_t)KWS_SLICE_SAMPLES) {
            signal_t signal;
            signal.total_length = KWS_SLICE_SAMPLES;
            signal.get_data     = kws_get_data;

            ei_impulse_result_t result;
            EI_IMPULSE_ERROR res =
                run_classifier_continuous(&signal, &result, false);

            if (res == EI_IMPULSE_OK) {
                for (int i = 0; i < EI_CLASSIFIER_LABEL_COUNT; i++) {
                    if (result.classification[i].value >= kws_threshold) {
                        LOG_INF("KWS: '%s' %.0f%%",
                                result.classification[i].label,
                                (double)(result.classification[i].value
                                         * 100.0f));
                    }
                }
            } else {
                LOG_WRN("kws: inference error %d", (int)res);
            }

            kws_slice_fill = 0;
        }
    }

    mic_block_free(buf);
}

static void kws_thread_fn(void *p1, void *p2, void *p3)
{
    ARG_UNUSED(p1);
    ARG_UNUSED(p2);
    ARG_UNUSED(p3);

    if (mic_open() < 0) {
        goto done;
    }

    kws_slice_fill = 0;
    run_classifier_init();

    LOG_INF("KWS: running  labels=%d  slice=%d samples  threshold=%.2f",
            EI_CLASSIFIER_LABEL_COUNT, KWS_SLICE_SAMPLES, (double)kws_threshold);

    mic_run(&kws_stop_req, kws_block_cb, NULL);

    run_classifier_deinit();
    mic_close();

done:
    k_mutex_lock(&kws_mutex, K_FOREVER);
    kws_active = false;
    k_mutex_unlock(&kws_mutex);
}

/* =========================================================================
 * Public C API
 * ========================================================================= */

extern "C" bool kws_is_active(void)
{
    k_mutex_lock(&kws_mutex, K_FOREVER);
    bool a = kws_active;
    k_mutex_unlock(&kws_mutex);
    return a;
}

/* =========================================================================
 * Shell commands
 * ========================================================================= */

static int cmd_kws_start(const struct shell *sh, size_t argc, char **argv)
{
    ARG_UNUSED(argc);
    ARG_UNUSED(argv);

    k_mutex_lock(&kws_mutex, K_FOREVER);

    if (kws_active) {
        shell_error(sh, "KWS already running -- use 'kws stop' first");
        k_mutex_unlock(&kws_mutex);
        return -EBUSY;
    }

    if (rec_is_active()) {
        shell_error(sh, "WAV recording in progress -- use 'record stop' first");
        k_mutex_unlock(&kws_mutex);
        return -EBUSY;
    }

    if (pitch_is_active()) {
        shell_error(sh, "Pitch detection is running -- use 'pitch stop' first");
        k_mutex_unlock(&kws_mutex);
        return -EBUSY;
    }

    atomic_set(&kws_stop_req, 0);
    kws_active = true;
    k_mutex_unlock(&kws_mutex);

    k_thread_create(&kws_thread, kws_stack,
                    K_THREAD_STACK_SIZEOF(kws_stack),
                    kws_thread_fn, NULL, NULL, NULL,
                    6, 0, K_NO_WAIT);
    k_thread_name_set(&kws_thread, "kws");

    shell_print(sh, "KWS started (threshold=%.2f) -- use 'kws stop' to end",
                (double)kws_threshold);
    return 0;
}

static int cmd_kws_stop(const struct shell *sh, size_t argc, char **argv)
{
    ARG_UNUSED(argc);
    ARG_UNUSED(argv);

    k_mutex_lock(&kws_mutex, K_FOREVER);
    bool active = kws_active;
    k_mutex_unlock(&kws_mutex);

    if (!active) {
        shell_error(sh, "KWS is not running");
        return -ENODEV;
    }

    shell_print(sh, "Stopping KWS...");
    atomic_set(&kws_stop_req, 1);

    int ret = k_thread_join(&kws_thread, K_SECONDS(5));
    if (ret < 0) {
        shell_error(sh, "KWS thread join timeout: %d", ret);
        return ret;
    }

    shell_print(sh, "KWS stopped");
    return 0;
}

static int cmd_kws_status(const struct shell *sh, size_t argc, char **argv)
{
    ARG_UNUSED(argc);
    ARG_UNUSED(argv);

    if (kws_is_active()) {
        shell_print(sh, "KWS running  threshold=%.2f  labels=%d",
                    (double)kws_threshold, EI_CLASSIFIER_LABEL_COUNT);
        for (int i = 0; i < EI_CLASSIFIER_LABEL_COUNT; i++) {
            shell_print(sh, "  [%d] %s", i,
                        ei_classifier_inferencing_categories[i]);
        }
    } else {
        shell_print(sh, "KWS idle");
    }
    return 0;
}

static int cmd_kws_threshold(const struct shell *sh, size_t argc, char **argv)
{
    if (argc < 2) {
        shell_print(sh, "Current threshold: %.2f", (double)kws_threshold);
        return 0;
    }

    char  *end;
    float  val = strtof(argv[1], &end);

    if (end == argv[1] || val < 0.0f || val > 1.0f) {
        shell_error(sh, "Invalid threshold (expected float 0.0 – 1.0)");
        return -EINVAL;
    }

    kws_threshold = val;
    shell_print(sh, "Threshold set to %.2f", (double)kws_threshold);
    return 0;
}

SHELL_STATIC_SUBCMD_SET_CREATE(sub_kws,
    SHELL_CMD_ARG(start, NULL,
                  "Start continuous keyword detection",
                  cmd_kws_start, 1, 0),
    SHELL_CMD_ARG(stop, NULL,
                  "Stop keyword detection",
                  cmd_kws_stop, 1, 0),
    SHELL_CMD_ARG(status, NULL,
                  "Show KWS state and detected labels",
                  cmd_kws_status, 1, 0),
    SHELL_CMD_ARG(threshold, NULL,
                  "[value]  Get or set detection threshold (0.0 – 1.0)",
                  cmd_kws_threshold, 1, 1),
    SHELL_SUBCMD_SET_END
);
SHELL_CMD_REGISTER(kws, &sub_kws, "Keyword spotting (Edge Impulse)", NULL);
```

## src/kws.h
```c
/*
 * Copyright (c) 2026 Nicolas Goualard
 * SPDX-License-Identifier: Apache-2.0
 *
 * Keyword Spotting (KWS) public C API.
 * Include this header from C files that need to query KWS state.
 */

#pragma once

#include <stdbool.h>

#ifdef __cplusplus
extern "C" {
#endif

/**
 * @brief Returns true if keyword spotting is currently running.
 */
#if CONFIG_APP_KWS
bool kws_is_active(void);
#else
static inline bool kws_is_active(void) { return false; }
#endif

#ifdef __cplusplus
}
#endif
```

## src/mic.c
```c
/*
 * Copyright (c) 2026 Nicolas Goualard
 * SPDX-License-Identifier: Apache-2.0
 */

#include "mic.h"

#include <zephyr/audio/dmic.h>
#include <zephyr/drivers/regulator.h>
#include <zephyr/device.h>
#include <zephyr/devicetree.h>
#include <zephyr/logging/log.h>

LOG_MODULE_REGISTER(mic, CONFIG_APP_LOG_LEVEL);

/*
 * 8 blocks: hardware double-buffering (2) + driver rx-queue (4) + reader
 * hold (1) + 1 spare.  Only one mode runs at a time so this covers all cases.
 */
#define MIC_SLAB_BLOCKS 8U
K_MEM_SLAB_DEFINE_STATIC(mic_slab, MIC_BLOCK_BYTES, MIC_SLAB_BLOCKS, 4);

static const struct device *mic_dmic;
static const struct device *mic_pwr;

int mic_open(void)
{
	mic_dmic = DEVICE_DT_GET(DT_NODELABEL(pdm0));
	mic_pwr  = DEVICE_DT_GET(DT_NODELABEL(mic_pwr));

	if (!device_is_ready(mic_pwr)) {
		LOG_ERR("mic_pwr not ready");
		return -ENODEV;
	}

	int ret = regulator_enable(mic_pwr);

	if (ret < 0) {
		LOG_ERR("regulator_enable: %d", ret);
		return ret;
	}
	k_sleep(K_MSEC(100));

	struct pcm_stream_cfg stream = {
		.pcm_rate   = MIC_SAMPLE_RATE,
		.pcm_width  = MIC_BITS,
		.block_size = MIC_BLOCK_BYTES,
		.mem_slab   = &mic_slab,
	};
	struct dmic_cfg cfg = {
		.io = {
			.min_pdm_clk_freq = 1000000,
			.max_pdm_clk_freq = 3200000,
			.min_pdm_clk_dc   = 40,
			.max_pdm_clk_dc   = 60,
		},
		.streams = &stream,
		.channel = {
			.req_chan_map_lo = dmic_build_channel_map(0, 0, PDM_CHAN_LEFT),
			.req_num_chan    = MIC_CHANNELS,
			.req_num_streams = 1,
		},
	};

	ret = dmic_configure(mic_dmic, &cfg);
	if (ret < 0) {
		LOG_ERR("dmic_configure: %d", ret);
		regulator_disable(mic_pwr);
		return ret;
	}

	ret = dmic_trigger(mic_dmic, DMIC_TRIGGER_START);
	if (ret < 0) {
		LOG_ERR("dmic_trigger START: %d", ret);
		regulator_disable(mic_pwr);
		return ret;
	}

	/* Discard the first block: PDM filter warm-up. */
	{
		void    *buf;
		uint32_t size;

		if (dmic_read(mic_dmic, 0, &buf, &size, MIC_BLOCK_MS * 2) == 0) {
			k_mem_slab_free(&mic_slab, buf);
		}
	}

	return 0;
}

int mic_run(atomic_t *stop_flag, mic_block_fn_t cb, void *user_data)
{
	while (!atomic_get(stop_flag)) {
		void    *buf;
		uint32_t size;

		int ret = dmic_read(mic_dmic, 0, &buf, &size, MIC_BLOCK_MS * 2);

		if (ret < 0) {
			LOG_ERR("dmic_read: %d", ret);
			return ret;
		}

		cb(buf, size, user_data);
	}
	return 0;
}

void mic_close(void)
{
	dmic_trigger(mic_dmic, DMIC_TRIGGER_STOP);

	void    *buf;
	uint32_t size;

	while (dmic_read(mic_dmic, 0, &buf, &size, 0) == 0) {
		k_mem_slab_free(&mic_slab, buf);
	}

	regulator_disable(mic_pwr);
}

void mic_block_free(void *buf)
{
	k_mem_slab_free(&mic_slab, buf);
}
```

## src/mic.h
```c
/*
 * Copyright (c) 2026 Nicolas Goualard
 * SPDX-License-Identifier: Apache-2.0
 *
 * Shared PDM microphone acquisition layer.
 *
 * A single 10-block slab and a unified open/run/close API replace the
 * per-mode PDM boilerplate in kws.cpp, pitch.c and main.c.
 *
 * Usage pattern in a mode thread:
 *
 *   int ret = mic_open();
 *   if (ret < 0) { ... }
 *   mic_run(&mode_stop_req, mode_block_cb, user_data);
 *   mic_close();
 *
 * The block callback MUST call mic_block_free(buf) when it is done with
 * the data.  mic_run() does NOT free blocks automatically so that
 * computationally heavy callbacks (pitch NSDF, KWS inference) can release
 * the slab slot early and let the driver keep filling new buffers.
 */

#pragma once

#include <stdint.h>
#include <zephyr/kernel.h>

/* Audio parameters shared across all modes. */
#define MIC_SAMPLE_RATE    16000U
#define MIC_BITS           16U
#define MIC_CHANNELS       1U
#define MIC_BLOCK_MS       100U
#define MIC_BLOCK_SAMPLES  (MIC_SAMPLE_RATE * MIC_BLOCK_MS / 1000U)  /* 1600 */
#define MIC_BLOCK_BYTES    (MIC_BLOCK_SAMPLES * MIC_CHANNELS * (MIC_BITS / 8U))  /* 3200 */

/*
 * Called by mic_run() for every PDM block.
 * The callee MUST call mic_block_free(buf) when done with the data.
 */
typedef void (*mic_block_fn_t)(void *buf, uint32_t size, void *user_data);

#ifdef __cplusplus
extern "C" {
#endif

/**
 * @brief Enable the microphone regulator, configure and start PDM.
 *
 * Discards the first block (filter warm-up) before returning.
 *
 * @return 0 on success, negative errno on error.
 */
int mic_open(void);

/**
 * @brief Read PDM blocks and invoke cb until *stop_flag is set.
 *
 * Blocks the calling thread.  The stop flag is sampled at the top of the
 * loop; at most one block after the flag is set will still be delivered.
 *
 * @return 0 on clean stop, negative errno on driver error.
 */
int mic_run(atomic_t *stop_flag, mic_block_fn_t cb, void *user_data);

/**
 * @brief Stop PDM, drain the driver queue, and disable the microphone regulator.
 */
void mic_close(void);

/**
 * @brief Return a slab block received in the callback to the shared pool.
 */
void mic_block_free(void *buf);

#ifdef __cplusplus
}
#endif
```
